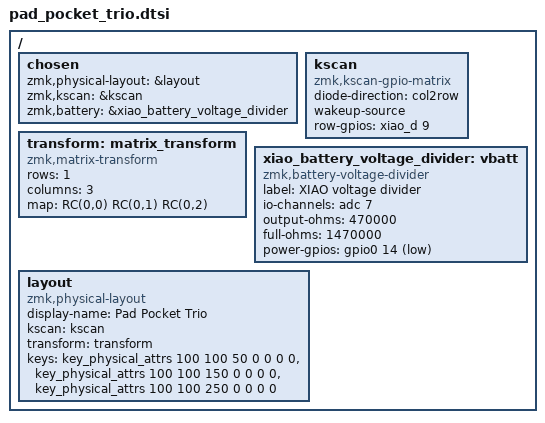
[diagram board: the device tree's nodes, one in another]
#include <physical_layouts.dtsi>
#include <dt-bindings/zmk/matrix_transform.h>

/ {
    chosen {
        zmk,physical-layout = &layout;
        zmk,kscan = &kscan;
        zmk,battery = &xiao_battery_voltage_divider;
    };

    kscan: kscan {
        compatible = "zmk,kscan-gpio-matrix";
        diode-direction = "col2row";
        wakeup-source;


        row-gpios = <&xiao_d 9 (GPIO_ACTIVE_HIGH | GPIO_PULL_DOWN)>;

    };

    transform: matrix_transform {
        compatible = "zmk,matrix-transform";
        rows = <1>;
        columns = <3>;

        map = <
        //   Key 1 | Key 2 | Key 2
            RC(0,0) RC(0,1) RC(0,2)
        >;

    };

    xiao_battery_voltage_divider: vbatt {
	status = "okay";
	compatible = "zmk,battery-voltage-divider";
	label = "XIAO voltage divider";
	io-channels = <&adc 7>;
	output-ohms = <470000>;
	full-ohms =  <1470000>;
	power-gpios = <&gpio0 14 (GPIO_ACTIVE_LOW)>;
    };
    
    layout: layout {
        compatible = "zmk,physical-layout";
        display-name = "Pad Pocket Trio";
        kscan = <&kscan>;
        transform = <&transform>;

        keys  //                     w   h    x    y     rot    rx    ry
            = <&key_physical_attrs 100 100   50    0       0     0     0>
            , <&key_physical_attrs 100 100  150    0       0     0     0>
            , <&key_physical_attrs 100 100  250    0       0     0     0>
            ;
    };
};
